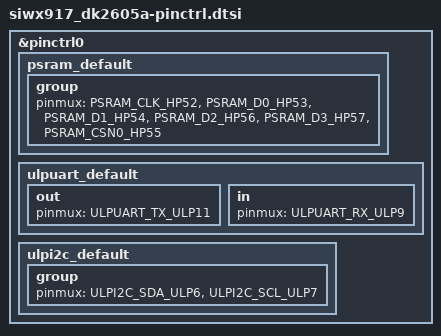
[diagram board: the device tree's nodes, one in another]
/*
 * Copyright (c) 2025 Silicon Laboratories Inc.
 * SPDX-License-Identifier: Apache-2.0
 */

#include <zephyr/dt-bindings/pinctrl/silabs/siwx91x-pinctrl.h>

&pinctrl0 {
	psram_default: psram_default {
		group {
			pinmux = <PSRAM_CLK_HP52>,
				 <PSRAM_D0_HP53>,
				 <PSRAM_D1_HP54>,
				 <PSRAM_D2_HP56>,
				 <PSRAM_D3_HP57>,
				 <PSRAM_CSN0_HP55>;
		};
	};

	ulpuart_default: ulpuart_default {
		out {
			pinmux = <ULPUART_TX_ULP11>;
		};

		in {
			pinmux = <ULPUART_RX_ULP9>;
		};
	};

	ulpi2c_default: ulpi2c_default {
		group {
			pinmux = <ULPI2C_SDA_ULP6>, <ULPI2C_SCL_ULP7>;
		};
	};
};
